# ESW3120 register map
Vendor: Shanghai Eastsoft Microelectronics Co.,Ltd.; Series: ARMCM3; File version: 1.2
CPU: CM3 r2p1, little endian, MPU, no FPU, 4 interrupt priority bits
Registers are 32-bit, read-write, reset 0x0 unless marked. A register's access mark holds for its fields unless they carry their own. Offsets are from the block's base; [hi:lo] are bit positions; 'fields as' and 'values as' point back to an identical list.

## TRNG
Base 0x40085C00
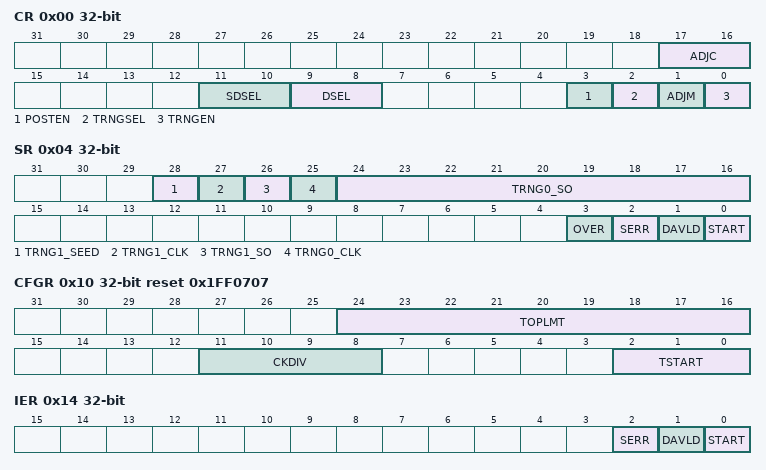
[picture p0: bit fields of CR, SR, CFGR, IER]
0x00 CR
  [17:16] ADJC, [11:10] SDSEL, [9:8] DSEL, [3] POSTEN, [2] TRNGSEL, [1] ADJM, [0] TRNGEN
0x04 SR read
  [28] TRNG1_SEED, [27] TRNG1_CLK, [26] TRNG1_SO, [25] TRNG0_CLK, [24:16] TRNG0_SO, [3] OVER, [2] SERR, [1] DAVLD, [0] START
0x08 DR read
  [31:0] DATA
0x0C SEED
0x10 CFGR reset 0x1FF0707
  [24:16] TOPLMT, [11:8] CKDIV, [2:0] TSTART
0x14 IER
  [2] SERR, [1] DAVLD, [0] START
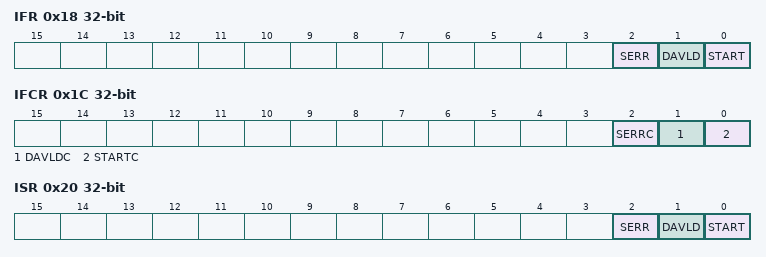
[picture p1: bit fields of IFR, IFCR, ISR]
0x18 IFR read
  [2] SERR, [1] DAVLD, [0] START
0x1C IFCR write1
  [2] SERRC, [1] DAVLDC, [0] STARTC
0x20 ISR read
  [2] SERR, [1] DAVLD, [0] START

## SYSCFG
Base 0x40080000
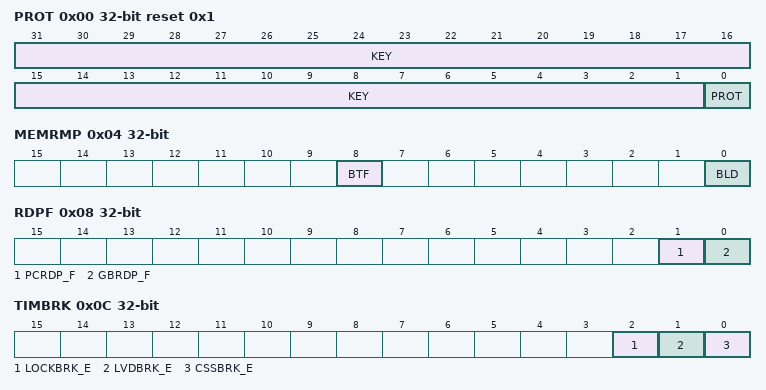
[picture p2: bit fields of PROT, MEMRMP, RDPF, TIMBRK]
0x00 PROT read reset 0x1
  [31:1] KEY write, [0] PROT
0x04 MEMRMP
  [8] BTF, [0] BLD
0x08 RDPF clear-write1
  [1] PCRDP_F, [0] GBRDP_F
0x0C TIMBRK
  [2] LOCKBRK_E, [1] LVDBRK_E, [0] CSSBRK_E

## RTC
Base 0x40048400
0x00 WPR read reset 0x1
  [0] WP
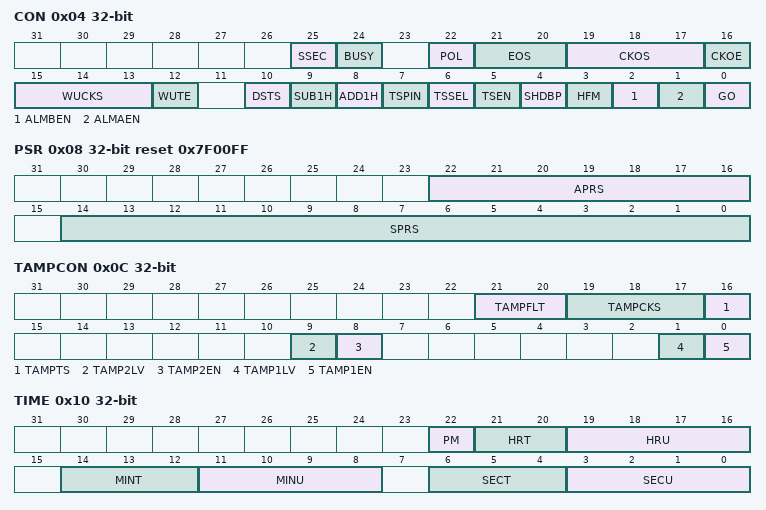
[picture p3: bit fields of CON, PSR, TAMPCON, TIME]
0x04 CON
  [25] SSEC read, [24] BUSY read, [22] POL, [21:20] EOS, [19:17] CKOS, [16] CKOE, [15:13] WUCKS, [12] WUTE, [10] DSTS, [9] SUB1H write1, [8] ADD1H write1, [7] TSPIN, [6] TSSEL, [5] TSEN, [4] SHDBP, [3] HFM, [2] ALMBEN, [1] ALMAEN, [0] GO
0x08 PSR reset 0x7F00FF
  [22:16] APRS, [14:0] SPRS
0x0C TAMPCON
  [21:20] TAMPFLT, [19:17] TAMPCKS, [16] TAMPTS, [9] TAMP2LV, [8] TAMP2EN, [1] TAMP1LV, [0] TAMP1EN
0x10 TIME
  [22] PM, [21:20] HRT, [19:16] HRU, [14:12] MINT, [11:8] MINU, [6:4] SECT, [3:0] SECU
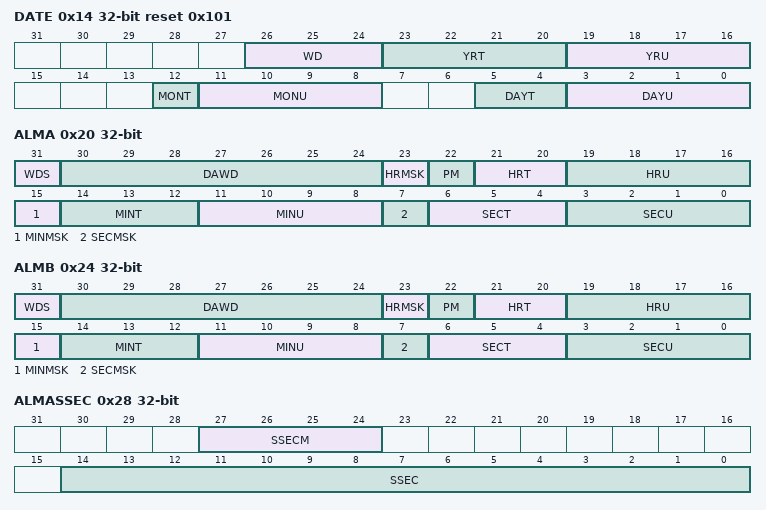
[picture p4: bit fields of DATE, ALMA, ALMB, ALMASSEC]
0x14 DATE reset 0x101
  [26:24] WD, [23:20] YRT, [19:16] YRU, [12] MONT, [11:8] MONU, [5:4] DAYT, [3:0] DAYU
0x18 SSEC read
  [15:0] VAL
0x1C WUMAT reset 0xFFFF
  [15:0] VAL
0x20 ALMA
  [31] WDS, [30:24] DAWD, [23] HRMSK, [22] PM, [21:20] HRT, [19:16] HRU, [15] MINMSK, [14:12] MINT, [11:8] MINU, [7] SECMSK, [6:4] SECT, [3:0] SECU
0x24 ALMB
  fields as ALMA
0x28 ALMASSEC
  [27:24] SSECM, [14:0] SSEC
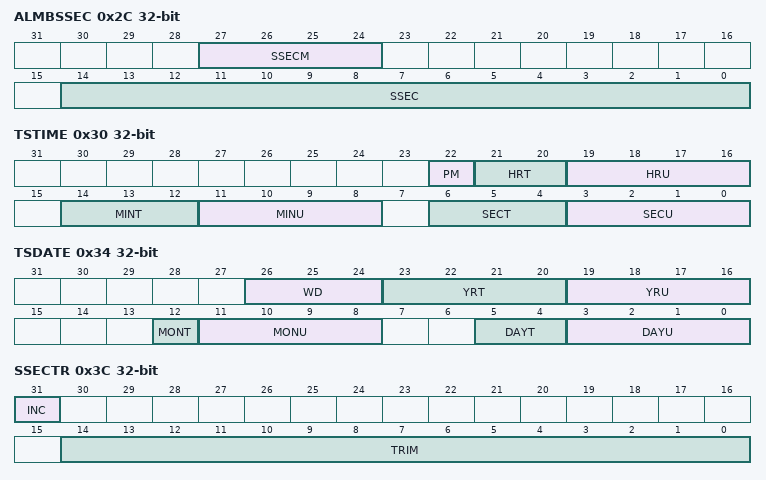
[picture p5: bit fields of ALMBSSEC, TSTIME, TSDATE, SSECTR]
0x2C ALMBSSEC
  [27:24] SSECM, [14:0] SSEC
0x30 TSTIME read
  fields as TIME
0x34 TSDATE read
  fields as DATE
0x38 TSSSEC read
  [15:0] SSEC
0x3C SSECTR write
  [31] INC, [14:0] TRIM
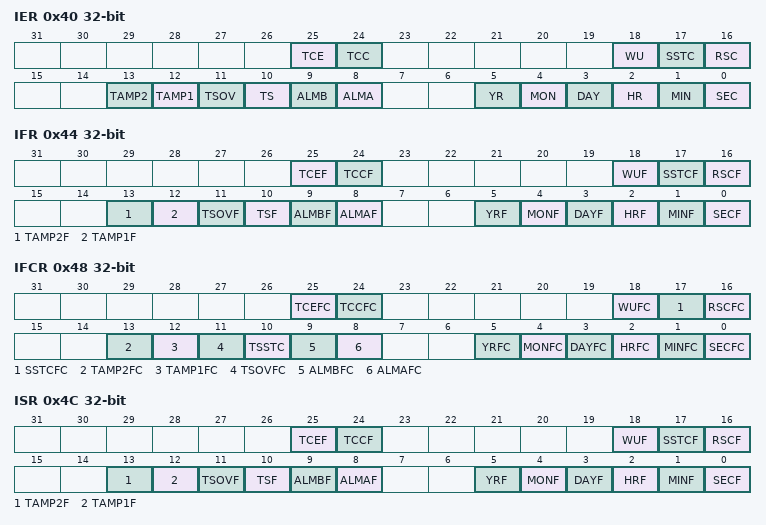
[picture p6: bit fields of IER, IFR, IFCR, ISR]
0x40 IER
  [25] TCE, [24] TCC, [18] WU, [17] SSTC, [16] RSC, [13] TAMP2, [12] TAMP1, [11] TSOV, [10] TS, [9] ALMB, [8] ALMA, [5] YR, [4] MON, [3] DAY, [2] HR, [1] MIN, [0] SEC
0x44 IFR read
  [25] TCEF, [24] TCCF, [18] WUF, [17] SSTCF, [16] RSCF, [13] TAMP2F, [12] TAMP1F, [11] TSOVF, [10] TSF, [9] ALMBF, [8] ALMAF, [5] YRF, [4] MONF, [3] DAYF, [2] HRF, [1] MINF, [0] SECF
0x48 IFCR write1
  [25] TCEFC, [24] TCCFC, [18] WUFC, [17] SSTCFC, [16] RSCFC, [13] TAMP2FC, [12] TAMP1FC, [11] TSOVFC, [10] TSSTC, [9] ALMBFC, [8] ALMAFC, [5] YRFC, [4] MONFC, [3] DAYFC, [2] HRFC, [1] MINFC, [0] SECFC
0x4C ISR read
  fields as IFR
0x50 CALWPR read reset 0x1
  [0] WP
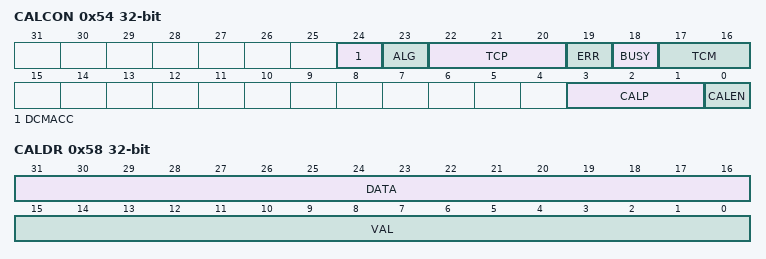
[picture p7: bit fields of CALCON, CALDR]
0x54 CALCON
  [24] DCMACC, [23] ALG, [22:20] TCP, [19] ERR read, [18] BUSY read, [17:16] TCM, [3:1] CALP, [0] CALEN
0x58 CALDR
  [31:16] DATA read, [15:0] VAL

## RMU
Base 0x40080800
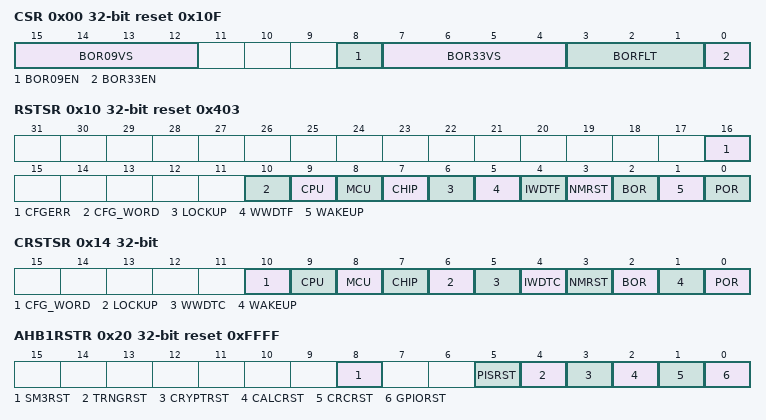
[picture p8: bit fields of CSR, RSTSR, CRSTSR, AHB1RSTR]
0x00 CSR reset 0x10F
  [15:12] BOR09VS, [8] BOR09EN, [7:4] BOR33VS, [3:1] BORFLT, [0] BOR33EN
0x10 RSTSR read reset 0x403
  [16] CFGERR, [10] CFG_WORD, [9] CPU, [8] MCU, [7] CHIP, [6] LOCKUP, [5] WWDTF, [4] IWDTF, [3] NMRST, [2] BOR, [1] WAKEUP, [0] POR
0x14 CRSTSR write
  [10] CFG_WORD, [9] CPU, [8] MCU, [7] CHIP, [6] LOCKUP, [5] WWDTC, [4] IWDTC, [3] NMRST, [2] BOR, [1] WAKEUP, [0] POR
0x20 AHB1RSTR trigger-write1 reset 0xFFFF
  [8] SM3RST, [5] PISRST, [4] TRNGRST, [3] CRYPTRST, [2] CALCRST, [1] CRCRST, [0] GPIORST
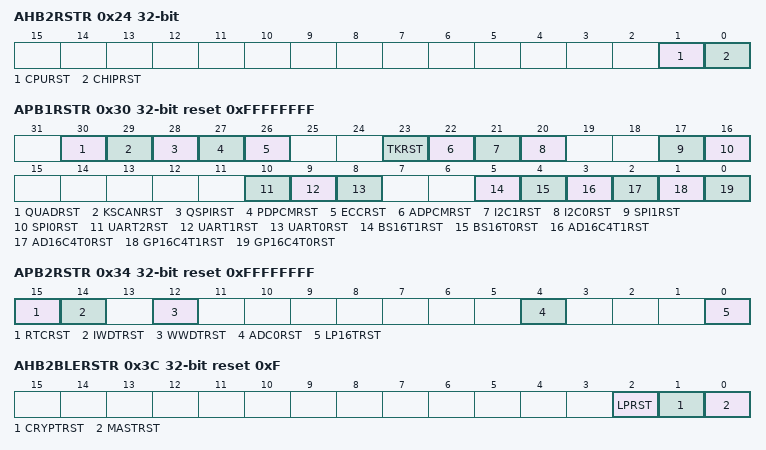
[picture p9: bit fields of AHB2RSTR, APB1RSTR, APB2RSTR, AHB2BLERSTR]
0x24 AHB2RSTR trigger-write1
  [1] CPURST, [0] CHIPRST
0x30 APB1RSTR trigger-write1 reset 0xFFFFFFFF
  [30] QUADRST, [29] KSCANRST, [28] QSPIRST, [27] PDPCMRST, [26] ECCRST, [23] TKRST, [22] ADPCMRST, [21] I2C1RST, [20] I2C0RST, [17] SPI1RST, [16] SPI0RST, [10] UART2RST, [9] UART1RST, [8] UART0RST, [5] BS16T1RST, [4] BS16T0RST, [3] AD16C4T1RST, [2] AD16C4T0RST, [1] GP16C4T1RST, [0] GP16C4T0RST
0x34 APB2RSTR trigger-write1 reset 0xFFFFFFFF
  [15] RTCRST, [14] IWDTRST, [12] WWDTRST, [4] ADC0RST, [0] LP16TRST
0x38 APB3RSTR trigger-write1 reset 0x3
  [0] BLEMDMRST
0x3C AHB2BLERSTR trigger-write1 reset 0xF
  [2] LPRST, [1] CRYPTRST, [0] MASTRST
